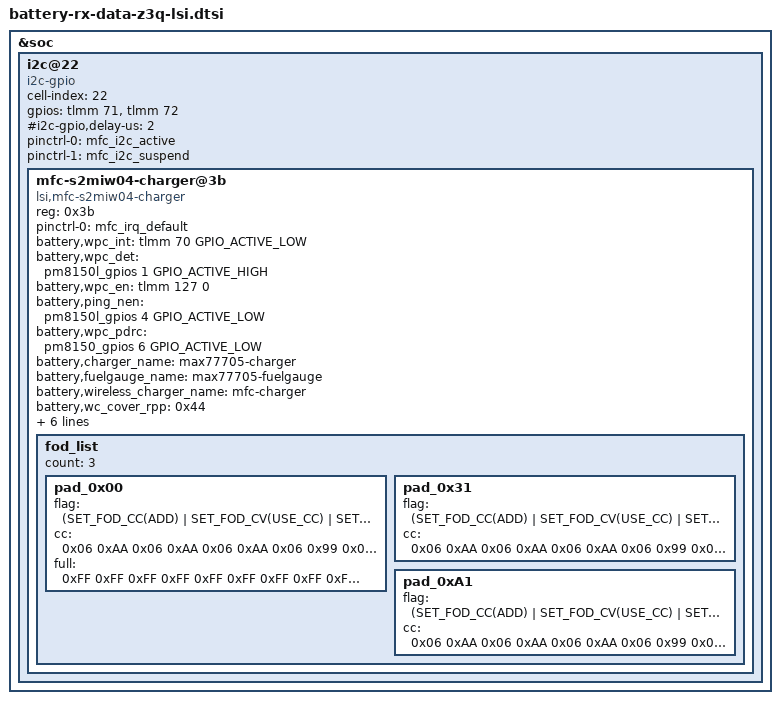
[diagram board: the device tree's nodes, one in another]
/* Copyright (c) 2014, The Linux Foundation. All rights reserved.
 *
 * This program is free software; you can redistribute it and/or modify
 * it under the terms of the GNU General Public License version 2 and
 * only version 2 as published by the Free Software Foundation.
 *
 * This program is distributed in the hope that it will be useful,
 * but WITHOUT ANY WARRANTY; without even the implied warranty of
 * MERCHANTABILITY or FITNESS FOR A PARTICULAR PURPOSE.  See the
 * GNU General Public License for more details.
 */

#define FOD_FLAG_NONE			0
#define FOD_FLAG_ADD			1
#define FOD_FLAG_USE_CC			2
#define FOD_FLAG_USE_DEFAULT	3
#define SET_FOD_CC(_flag)		(FOD_FLAG_ ##_flag)
#define SET_FOD_CV(_flag)		(FOD_FLAG_ ##_flag << 4)
#define SET_FOD_FULL(_flag)		(FOD_FLAG_ ##_flag << 8)

&soc {
	i2c@22 {
		status = "ok";
		cell-index = <22>;
		compatible = "i2c-gpio";
		gpios = <&tlmm 71 0 /* sda */
				&tlmm 72 0 /* scl */
		>;
		#i2c-gpio,delay-us = <2>;
		#address-cells = <1>;
		#size-cells = <0>;

		pinctrl-names = "default", "sleep";
		pinctrl-0 = <&mfc_i2c_active>;
		pinctrl-1 = <&mfc_i2c_suspend>;

		mfc-s2miw04-charger@3b {
			compatible = "lsi,mfc-s2miw04-charger";
			reg = <0x3b>;
			status = "okay";

			pinctrl-names = "default";
			pinctrl-0 = <&mfc_irq_default>;

			battery,wpc_int = <&tlmm 70 GPIO_ACTIVE_LOW>; /* MFC_AP_INT */
			battery,wpc_det = <&pm8150l_gpios 1 GPIO_ACTIVE_HIGH>; /* WPC_DET */
			battery,wpc_en = <&tlmm 127 0>; /* WPC_EN */
			battery,ping_nen = <&pm8150l_gpios 4 GPIO_ACTIVE_LOW>; /* PING_nEN */
			battery,wpc_pdrc = <&pm8150_gpios 6 GPIO_ACTIVE_LOW>;

			battery,charger_name = "max77705-charger";
			battery,fuelgauge_name = "max77705-fuelgauge";
			battery,wireless_charger_name = "mfc-charger";
			battery,wc_cover_rpp = <0x44>;
			battery,phone_fod_threshold = <0x3b>;
			battery,oc_fod1 = <1100>;
			battery,tx_gear_min_op_freq_delay = <4000>;
			battery,wireless20_vout_list = <9 9 9>; /* WIRELESS_VOUT_11V, 11V, 11V */
			battery,wireless20_vrect_list = <10 11 11>; /* MFC_AFC_CONF_12V_TX, 12.5V, 12.5V */
			battery,wireless20_max_power_list = <2 3 3>; /* SEC_WIRELESS_RX_POWER_12W, 15W, 15W */

			fod_list {
				count = <3>;

				pad_0x00 { /* DEFAULT */
					flag = <(SET_FOD_CC(ADD) | SET_FOD_CV(USE_CC) | SET_FOD_FULL(ADD))>;
					cc = <0x06 0xAA 0x06 0xAA 0x06 0xAA 0x06 0x99 0x06 0x99 0x06 0x99 0x0C 0x85 0x0C 0x85 0x08 0x9E 0x08 0x9E>;
					full = <0xFF 0xFF 0xFF 0xFF 0xFF 0xFF 0xFF 0xFF 0xFF 0xFF 0xFF 0xFF 0xFF 0xFF 0xFF 0xFF 0xFF 0xFF 0xFF 0xFF>;
				};

				pad_0x31 { /* DREAM PAD - STAND */
					flag = <(SET_FOD_CC(ADD) | SET_FOD_CV(USE_CC) | SET_FOD_FULL(USE_DEFAULT))>;
					cc = <0x06 0xAA 0x06 0xAA 0x06 0xAA 0x06 0x99 0x06 0x99 0x06 0x99 0x0C 0x71 0x0C 0x71 0x08 0x9E 0x08 0x9E>;
				};

				pad_0xA1 { /* DAVINCHI PAD(V) */
					flag = <(SET_FOD_CC(ADD) | SET_FOD_CV(USE_CC) | SET_FOD_FULL(USE_DEFAULT))>;
					cc = <0x06 0xAA 0x06 0xAA 0x06 0xAA 0x06 0x99 0x06 0x99 0x06 0x99 0x0C 0x85 0x0C 0x85 0x08 0x9E 0x08 0xE1>;
				};
			};
		};
	};
};
